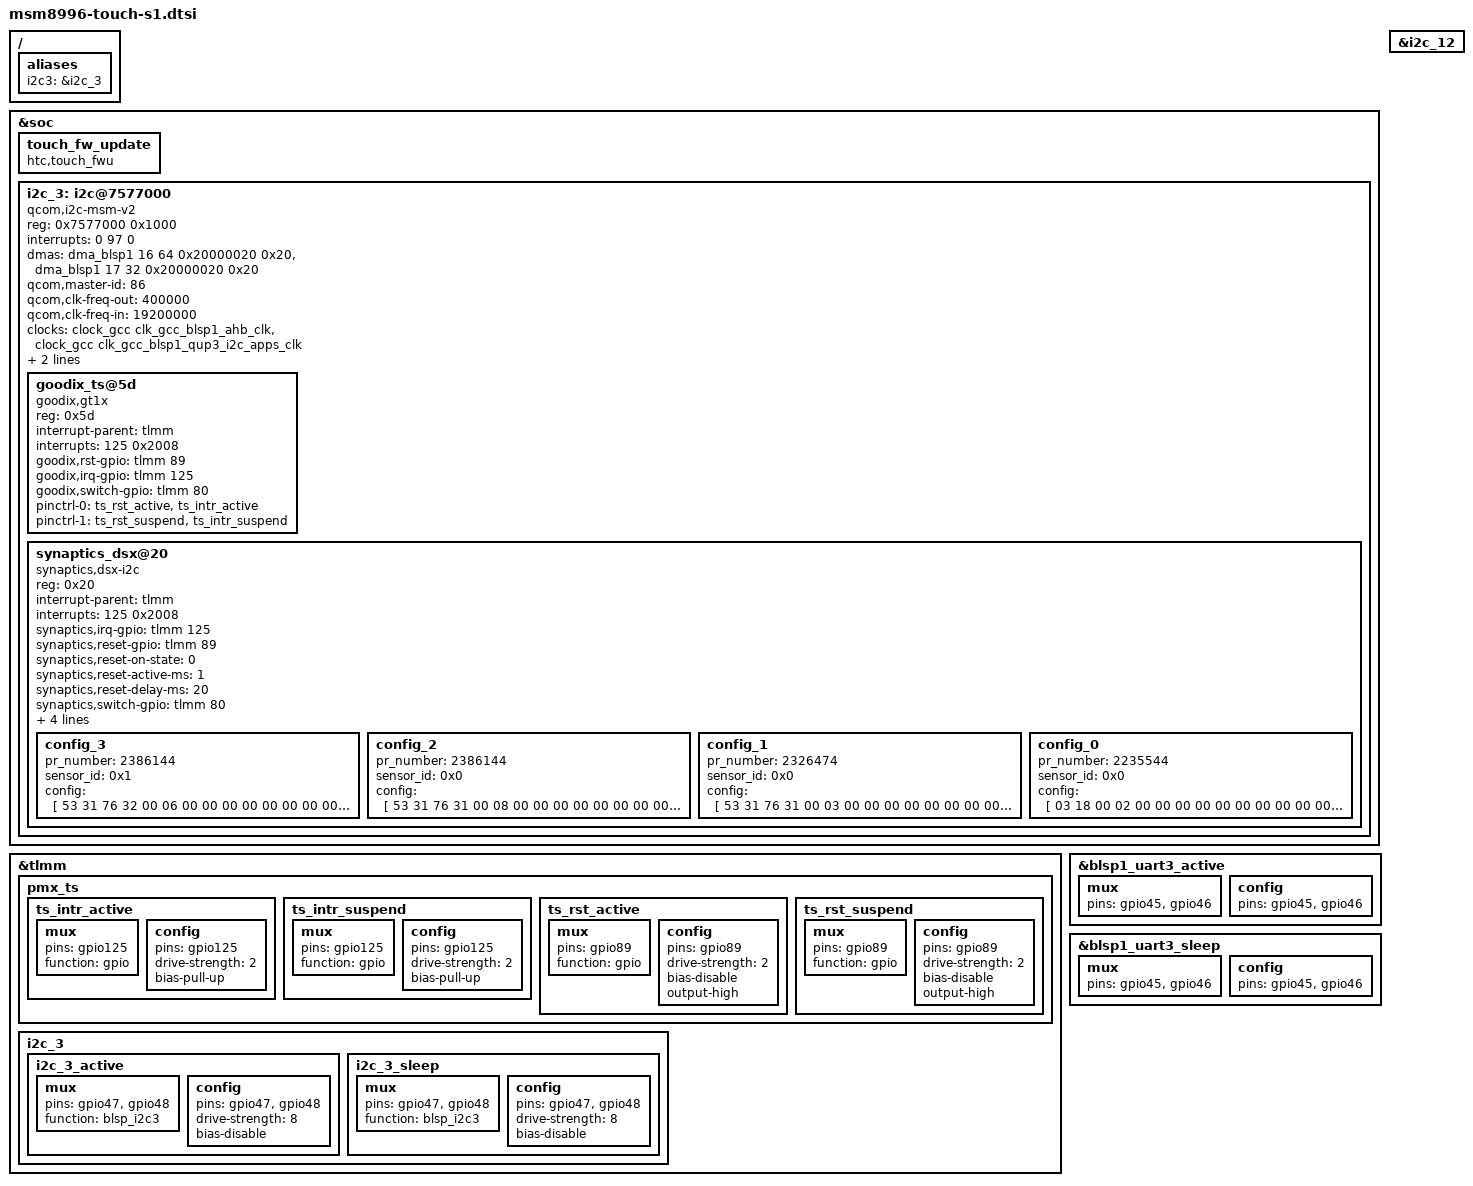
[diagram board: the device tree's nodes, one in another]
&soc {
	touch_fw_update {
		compatible = "htc,touch_fwu";
	};
};

&tlmm {
	pmx_ts {
		ts_intr_active:ts_intr_active {
			mux {
				pins = "gpio125";
				function = "gpio";
			};

			config {
				pins = "gpio125";
				drive-strength = <2>;
				bias-pull-up;
			};
		};
		ts_intr_suspend:ts_intr_suspend {
			mux {
				pins = "gpio125";
				function = "gpio";
			};

			config {
				pins = "gpio125";
				drive-strength = <2>;
				bias-pull-up;
			};
		};

		ts_rst_active:ts_rst_active {
			mux {
				pins = "gpio89";
				function = "gpio";
			};

			config {
				pins = "gpio89";
				drive-strength = <2>;
				bias-disable; /* No PULL */
				output-high;
			};
		};
		ts_rst_suspend:ts_rst_suspend {
			mux {
				pins = "gpio89";
				function = "gpio";
			};

			config {
				pins = "gpio89";
				drive-strength = <2>;
				bias-disable;
				output-high;
			};
		};
	};

	i2c_3 {
		i2c_3_active: i2c_3_active {
			mux {
				pins = "gpio47", "gpio48";
				function = "blsp_i2c3";
			};

			config {
				pins = "gpio47", "gpio48";
				drive-strength = <8>;
				bias-disable;
			};
		};

		i2c_3_sleep: i2c_3_sleep {
			mux {
				pins = "gpio47", "gpio48";
				function = "blsp_i2c3";
			};

			config {
				pins = "gpio47", "gpio48";
				drive-strength = <8>;
				bias-disable;
			};
		};
	};
};

&blsp1_uart3_active {
	mux {
		pins = "gpio45", "gpio46";
	};

	config {
		pins = "gpio45", "gpio46";
	};
};

&blsp1_uart3_sleep {
	mux {
		pins = "gpio45", "gpio46";
	};

	config {
		pins = "gpio45", "gpio46";
	};
};

/ {
	aliases {
		i2c3 = &i2c_3;
	};
};

&soc {
	i2c_3: i2c@7577000 { /* BLSP1 QUP3 */
		compatible = "qcom,i2c-msm-v2";
		#address-cells = <1>;
		#size-cells = <0>;
		reg = <0x7577000  0x1000>;
		reg-names = "qup_phys_addr";
		interrupt-names = "qup_irq";
		interrupts = <0 97 0>;
		dmas = <&dma_blsp1 16 64 0x20000020 0x20>,
			<&dma_blsp1 17 32 0x20000020 0x20>;
		dma-names = "tx", "rx";
		qcom,master-id = <86>;
		qcom,clk-freq-out = <400000>;
		qcom,clk-freq-in  = <19200000>;
		clock-names = "iface_clk", "core_clk";
		clocks = <&clock_gcc clk_gcc_blsp1_ahb_clk>,
			 <&clock_gcc clk_gcc_blsp1_qup3_i2c_apps_clk>;
		pinctrl-names = "i2c_active", "i2c_sleep";
		pinctrl-0 = <&i2c_3_active>;
		pinctrl-1 = <&i2c_3_sleep>;
	};
};

&i2c_12 {
	/delete-node/ synaptics@20;
};

&i2c_3 {
	goodix_ts@5d {
		compatible = "goodix,gt1x";
		reg = <0x5d>;
		interrupt-parent = <&tlmm>;
		interrupts = <125 0x2008>;
//		vdd_ana-supply = <&pm8994_l22>;
//		vcc_i2c-supply = <&pm8994_l18>;
		goodix,rst-gpio = <&tlmm 89 0x00>;
		goodix,irq-gpio = <&tlmm 125 0x00>;
		goodix,switch-gpio = <&tlmm 80 0x00>;
		pinctrl-names = "pmx_ts_active", "pmx_ts_suspend";
		pinctrl-0 = <&ts_rst_active &ts_intr_active>;
		pinctrl-1 = <&ts_rst_suspend &ts_intr_suspend>;
	};

	/delete-node/ synaptics_dsx@20;
	synaptics_dsx@20 {
		compatible = "synaptics,dsx-i2c";
		reg = <0x20>;
		interrupt-parent = <&tlmm>;
		interrupts = <125 0x2008>;
		synaptics,irq-gpio = <&tlmm 125 0x2008>;  /* IRQF_ONESHOT | IRQF_TRIGGER_LOW */
		synaptics,reset-gpio = <&tlmm 89 0x00>;
		synaptics,reset-on-state = <0>;
		synaptics,reset-active-ms = <1>;
		synaptics,reset-delay-ms = <20>;
		synaptics,switch-gpio = <&tlmm 80 0x00>;
		synaptics,update-feature = <3>;
		synaptics,tw-pin-mask = <0x3>;
		pinctrl-names = "pmx_ts_active", "pmx_ts_suspend";
		pinctrl-0 = <&ts_rst_active &ts_intr_active>;
		pinctrl-1 = <&ts_rst_suspend &ts_intr_suspend>;

		config_3 {
			pr_number     = <2386144>;
			sensor_id = <0x1>;
			config = [
				53 31 76 32 00 06 00 00
				00 00 00 00 00 00 00 00
				00 00 00 00 00 00 00 00
				00 00 00 00 00 00 00 00
				00 0F 01 0F 05 51 0E 37
				04 7F 07 46 3E 2B 3F 00
				00 20 20 10 1C 1E 05 CA
				0D B1 01 2D 1D 00 1B 00
				B1 CD 49 CE 25 0D 05 8C
				00 00 14 16 7D 0F 0A 87
				00 01 01 07 04 04 32 28
				08 7D 26 26 80 80 00 00
				C8 01 64 00 05 0A 00 FF
				05 01 28 FF C0 53 5B 80
				48 26 00 40 40 3C 50 00
				00 00 00 37 04 7F 07 3C
				32 00 00 00 00 37 04 7F
				07 1E 05 1E 04 0A 04 0A
				00 0A 04 04 00 0A 78 02
				00 7D 00 02 00 C8 00 00
				00 96 00 00 00 00 01 05
				0A 00 00 00 78 00 96 00
				32 00 00 00 00 00 00 00
				00 00 0D 00 00 14 03 0C
				0F 0A 00 4B 00 00 FF FF
				FF FF FF FF FF FF FF FF
				FF FF FF FF FF FF FF FF
				FF FF FF FF FF FF FF FF
				FF FF FF FF FF FF FF 00
				01 00 00 32 00 14 00 14
				00 64 00 64 00 10 00 10
				00 7D 00 7D 00 40 66 58
				1B 28 00 FF FF FF FF FF
				FF FF FF FF FF FF FF FF
				FF FF FF 01 00 00 00 00
				00 00 00 00 00 00 00 00
				00 00 00 00 00 00 00 00
				00 00 FF 00 FF 14 55 09
				0E 3C 0A 0F 64 64 00 00
				00 00 00 00 00 00 00 00
				00 00 00 00 00 00 00 00
				FF FF FF FF FF FF FF FF
				FF FF FF FF FF FF FF FF
				FF FF FF FF FF FF FF FF
				FF FF FF FF FF FF FF FF
				FF FF FF FF FF FF FF FF
				FF FF FF FF FF FF FF FF
				FF FF FF FF FF FF FF FF
				FF FF FF FF FF FF FF FF
				00 00 96 00 80 04 1B 00
				00 FF E8 03 FF FF BF 0A
				B8 0B 00 C0 80 04 10 0A
				18 00 79 08 0F 00 00 C8
				00 03 00 06 06 07 07 00
				C8 00 01 04 83 36 00 16
				00 00 00 02 00 01 2D 84
				35 00 16 00 01 00 05 00
				02 27 04 34 00 15 00 02
				00 05 00 02 28 83 33 00
				15 00 03 00 05 00 02 28
				83 32 00 14 00 04 00 05
				00 02 29 03 31 00 14 00
				05 00 05 00 02 29 83 2F
				00 13 00 07 00 03 00 01
				24 03 2D 00 13 00 09 00
				03 00 01 25 03 03 03 03
				03 03 03 03 03 03 03 03
				03 03 03 03 00 00 00 00
				00 00 00 00 00 00 00 00
				00 00 00 00 00 00 21 00
				06 00 28 00 0A 19 00 01
				1B 01 00 78 00 28 00 28
				00 3C 00 1E 03 0C 0C 14
				28 04 00 00 00 00 00 00
				00 00 00 00 15 00 80 07
				01 07 07 1D 1D 00 00 07
				07 01 07 07 1D 1D 00 00
				07 04 04 50 00 07 03 00
				36 22 00 05 0B 00 22 02
				00 00 00 0D 99 99 55 0D
				00 00 00 0D 00 00 00 0D
				AA AA 00 01 00 00 01 01
				00 01 00 80 80 80 80 80
				80 80 80 80 80 80 80 80
				80 80 80 80 80 80 80 80
				80 80 80 80 80 80 80 80
				80 80 80 80 80 80 80 80
				80 80 80 80 80 80 80 80
				80 80 80 80 80 80 80 80
				80 80 80 80 80 80 80 80
				80 80 80 80 80 80 80 00
				00 00 FF FF FF FF FF FF
				FF FF 51 51 51 51 CD 0D
				04 83 10 10 10 10 61 24
				64 01 16 12 11 0F 10 0B
				0A 05 04 18 1A 0D 13 0E
				08 09 FF FF FF FF FF FF
				FF FF FF FF FF FF FF FF
				FF FF FF FF 2F 28 29 2A
				2C 2B 26 25 23 24 22 35
				39 36 37 33 32 2D 27 34
				38 31 3A 3B 3E 3D 3C 3F
				FF FF FF FF FF FF 00 10
				00 10 00 10 00 10 80 80
				80 80 80 80 80 80 80 80
				80 80 80 80 80 80 80 80
				80 80 80 80 80 80 80 80
				80 80 80 80 80 80 80 80
				C0 B3 A6 9A 8D 80 80 80
				80 80 80 80 80 80 80 80
				80 80 80 80 80 80 80 80
				80 80 80 80 80 80 80 80
				80 80 00 18 00 18 00 10
				00 10 00 00 1C 1D 1E 1F
				FF FF FF FF 00 00 0F 00
				44 44 A0
			];
		};

		config_2 {
			pr_number     = <2386144>;
			sensor_id = <0x0>;
			config = [
				53 31 76 31 00 08 00 00
				00 00 00 00 00 00 00 00
				00 00 00 00 00 00 00 00
				00 00 00 00 00 00 00 00
				00 07 01 0F 05 51 0E 37
				04 7F 07 46 3E 2B 3F 00
				00 20 00 10 1C 1E 05 BF
				0F 31 02 2D 14 02 14 02
				C0 DA C0 DA 25 0D 05 8C
				00 00 10 12 82 0F 0A 78
				00 01 01 07 04 04 32 28
				08 7D 26 26 80 80 00 00
				C8 01 64 00 05 28 00 FF
				05 01 28 FF C0 53 5B 80
				52 1A 00 40 3A 46 50 00
				00 00 00 4C 04 6C 07 3C
				32 00 00 00 00 4C 04 6C
				07 1E 05 1E 04 0A 04 0A
				00 0A 04 04 00 0A 78 02
				00 7D 00 02 00 C8 00 00
				00 96 00 00 00 00 01 05
				0A 00 00 00 78 00 96 00
				32 00 00 00 00 00 00 00
				00 00 0D 00 00 14 03 0C
				0F 0A 00 4B 00 00 FF FF
				FF FF FF FF FF FF FF FF
				FF FF FF FF FF FF FF FF
				FF FF FF FF FF FF FF FF
				FF FF FF FF FF FF FF 00
				01 00 00 32 00 14 00 14
				00 64 00 64 00 10 00 10
				00 7D 00 7D 00 40 66 58
				1B 28 00 FF FF FF FF FF
				FF FF FF FF FF FF FF FF
				FF FF FF 01 00 00 00 00
				00 00 00 00 00 00 00 00
				00 00 00 00 00 00 00 00
				00 00 FF 00 FF 14 55 09
				0E 3C 0A 0F 64 64 00 00
				00 00 00 00 00 00 00 00
				00 00 00 00 00 00 00 00
				FF FF FF FF FF FF FF FF
				FF FF FF FF FF FF FF FF
				FF FF FF FF FF FF FF FF
				FF FF FF FF FF FF FF FF
				FF FF FF FF FF FF FF FF
				FF FF FF FF FF FF FF FF
				FF FF FF FF FF FF FF FF
				FF FF FF FF FF FF FF FF
				00 00 60 00 80 04 1B 00
				00 FF DC 05 FF FF CC 03
				40 1F 00 C0 80 04 10 0A
				18 00 79 08 06 00 01 B8
				0B 04 00 02 02 07 07 05
				B8 0B 01 04 83 36 00 16
				00 00 00 02 00 01 2D 84
				35 00 16 00 01 00 05 00
				02 27 04 34 00 15 00 02
				00 05 00 02 28 83 33 00
				15 00 03 00 05 00 02 28
				83 32 00 14 00 04 00 05
				00 02 29 03 31 00 14 00
				05 00 05 00 02 29 83 2F
				00 13 00 07 00 03 00 01
				24 03 2D 00 13 00 09 00
				03 00 01 25 03 03 03 03
				03 03 03 03 03 03 03 03
				03 03 03 03 00 00 00 00
				00 00 00 00 00 00 00 00
				00 00 00 00 00 00 21 00
				06 00 50 00 0A 19 00 01
				1B 01 06 46 00 28 00 28
				00 64 00 1E 03 0C 0C 14
				28 04 00 00 00 00 00 00
				00 00 00 00 15 00 80 07
				01 07 07 1D 1D 00 00 07
				07 01 07 07 1D 1D 00 00
				07 04 04 50 00 07 03 00
				36 22 00 05 0B 00 22 02
				00 00 00 0D DD DD 55 0D
				22 22 00 0D EE EE 00 0D
				EE EE AA 01 00 DA 00 01
				00 01 00 80 80 80 80 80
				80 80 80 80 80 80 80 80
				80 80 80 80 80 80 80 80
				80 80 80 80 80 80 80 80
				80 80 80 80 80 80 80 80
				80 80 80 80 80 80 80 80
				80 80 80 80 80 80 80 80
				80 80 80 80 80 80 80 80
				80 80 80 80 80 80 80 00
				00 00 FF FF FF FF FF FF
				FF FF 51 51 51 51 CD 0D
				04 83 10 10 10 10 61 24
				64 01 12 18 1A 38 36 31
				35 32 3A 37 14 34 15 33
				17 11 FF FF FF FF FF FF
				FF FF FF FF FF FF FF FF
				FF FF FF FF 30 28 2F 2A
				29 2C 27 2B 1B 1D 1E 1F
				1C 0D 10 0F 0C 07 0E 08
				09 03 06 02 0A 0B 04 05
				FF FF FF FF FF FF 00 10
				00 10 00 10 00 10 80 80
				80 80 80 80 80 80 80 80
				80 80 80 80 80 80 80 80
				80 80 80 80 80 80 80 80
				80 80 80 80 80 80 80 80
				C0 B3 A6 9A 8D 80 80 80
				80 80 80 80 80 80 80 80
				80 80 80 80 80 80 80 80
				80 80 80 80 80 80 80 80
				80 80 00 18 00 18 00 10
				00 10 00 00 16 19 24 39
				FF FF FF FF 0B 0B 04 00
				44 44 A0
			];
		};

		config_1 {
			pr_number     = <2326474>;
			sensor_id = <0x0>;
			config = [
				53 31 76 31 00 03 00 00
				00 00 00 00 00 00 00 00
				00 00 00 00 00 00 00 00
				00 00 00 00 00 00 00 00
				00 07 03 1E 05 51 0E 38
				04 80 07 46 3E 2B 3F 00
				00 20 00 10 1C 1E 05 BF
				0F 31 02 2D 14 02 14 02
				84 D2 81 D1 25 0D 05 8C
				00 00 0F 12 82 0F 0A 78
				00 01 01 07 04 04 32 28
				08 7D 26 26 80 80 00 00
				C8 01 64 00 05 0A 00 FF
				05 01 28 FF C0 53 5B 80
				4D 14 00 40 3A 32 50 00
				00 00 00 4C 04 6C 07 3C
				32 00 00 00 00 4C 04 6C
				07 1E 05 1E 04 0A 04 0A
				00 0A 04 04 00 0A 78 02
				00 7D 00 02 00 C8 00 00
				00 96 00 00 00 00 01 05
				0A 00 00 00 78 00 96 00
				32 00 00 00 00 00 00 00
				00 00 0D 00 00 14 03 0C
				0F 0A 00 4B 00 00 FF FF
				FF FF FF FF FF FF FF FF
				FF FF FF FF FF FF FF FF
				FF FF FF FF FF FF FF FF
				FF FF FF FF FF FF FF 00
				01 00 00 32 00 14 00 14
				00 64 00 64 00 10 00 10
				00 7D 00 7D 00 40 66 58
				1B 28 00 FF FF FF FF FF
				FF FF FF FF FF FF FF FF
				FF FF FF 01 00 00 00 00
				00 00 00 00 00 00 00 00
				00 00 00 00 00 00 00 00
				00 00 FF 00 FF 14 55 09
				0E 3C 0A 0F 64 64 00 00
				00 00 00 00 00 00 00 00
				00 00 00 00 00 00 00 00
				FF FF FF FF FF FF FF FF
				FF FF FF FF FF FF FF FF
				FF FF FF FF FF FF FF FF
				FF FF FF FF FF FF FF FF
				FF FF FF FF FF FF FF FF
				FF FF FF FF FF FF FF FF
				FF FF FF FF FF FF FF FF
				FF FF FF FF FF FF FF FF
				00 00 60 00 80 04 1B 00
				00 FF 2C 01 FF FF CC 03
				E8 03 00 C0 80 04 10 0A
				18 00 79 08 08 00 01 2C
				01 06 00 02 02 07 07 05
				FA 00 01 04 83 36 00 16
				00 00 00 02 00 01 2D 84
				35 00 16 00 01 00 05 00
				02 27 04 34 00 15 00 02
				00 05 00 02 28 83 33 00
				15 00 03 00 05 00 02 28
				83 32 00 14 00 04 00 05
				00 02 29 03 31 00 14 00
				05 00 05 00 02 29 83 2F
				00 13 00 07 00 03 00 01
				24 03 2D 00 13 00 09 00
				03 00 01 25 03 03 03 03
				03 03 03 03 03 03 03 03
				03 03 03 03 00 00 00 00
				00 00 00 00 00 00 00 00
				00 00 00 00 00 00 21 00
				06 00 A6 00 14 32 00 01
				1B 01 06 46 46 50 00 50
				00 50 50 1E 03 0C 0C 14
				28 04 00 00 00 00 00 00
				00 00 00 00 15 00 80 07
				01 07 07 1D 1D 00 00 07
				07 01 07 07 1D 1D 00 00
				07 04 04 50 00 07 03 00
				36 22 00 05 0B 00 22 02
				00 00 00 0D DD DD 55 0D
				22 22 00 01 50 0D 00 00
				00 0D AA AA 00 00 00 00
				FF FF FF FF FF FF FF FF
				51 51 51 51 CD 0D 04 83
				10 10 10 10 61 24 64 01
				12 18 1A 38 36 31 35 32
				3A 37 14 34 15 33 17 11
				FF FF FF FF FF FF FF FF
				FF FF FF FF FF FF FF FF
				FF FF 30 28 2F 2A 29 2C
				27 2B 1B 1D 1E 1F 1C 0D
				10 0F 0C 07 0E 08 09 03
				06 02 0A 0B 04 05 FF FF
				FF FF FF FF 00 10 00 10
				00 10 00 10 80 80 80 80
				80 80 80 80 80 80 80 80
				80 80 80 80 80 80 80 80
				80 80 80 80 80 80 80 80
				80 80 80 80 80 80 80 80
				80 80 80 80 80 80 80 80
				80 80 80 80 80 80 80 80
				80 80 80 80 80 80 80 80
				80 80 80 80 80 80 80 80
				00 10 00 10 00 10 00 10
				00 00 16 19 24 39 FF FF
				FF FF 0B 0B 04 00 44 44
				78
			];
		};

		config_0 {
			pr_number     = <2235544>;
			sensor_id = <0x0>;
			config = [
				03 18 00 02 00 00 00 00
				00 00 00 00 00 00 00 00
				00 00 00 00 00 00 00 00
				00 00 00 00 00 00 00 00
				04 7F 03 1E 05 51 0E 37
				04 7F 07 46 3E 2F 3F 03
				03 03 03 10 1C 1E 05 F5
				28 1E 05 28 30 00 30 00
				F0 D2 F0 D2 25 0D 05 8C
				00 00 05 0F 80 0F 0A 20
				00 01 01 07 04 04 0A C0
				19 64 26 26 80 80 00 00
				C8 C0 53 5B 80 5A 19 01
				40 40 32 50 00 00 00 00
				4C 04 6C 07 3C 32 00 00
				00 00 4C 04 6C 07 1E 05
				1E 04 0A 04 0A 00 0A 04
				04 00 0A 78 02 00 7D 00
				02 00 C8 00 00 00 96 00
				00 00 00 00 15 0A 00 00
				00 78 00 96 00 32 00 00
				00 00 00 00 00 00 00 0D
				00 00 14 03 0C 0F 0A 00
				4B 00 00 FF FF FF FF FF
				FF FF FF FF FF FF FF FF
				FF FF FF FF FF FF FF FF
				FF FF FF FF FF FF FF FF
				FF FF FF FF 00 01 00 00
				32 00 14 00 14 00 64 00
				64 00 10 00 10 00 7D 00
				7D 00 40 66 58 1B 28 00
				FF FF FF FF FF FF FF FF
				FF FF FF FF FF FF FF FF
				01 00 00 00 00 00 00 00
				00 00 00 00 00 00 00 00
				00 00 00 00 00 00 00 FF
				00 FF 14 55 09 0E 3C 0A
				0F 64 64 00 00 00 00 00
				00 00 00 00 00 00 00 00
				00 00 00 00 00 FF FF FF
				FF FF FF FF FF FF FF FF
				FF FF FF FF FF FF FF FF
				FF FF FF FF FF FF FF FF
				FF FF FF FF FF FF FF FF
				FF FF FF FF FF FF FF FF
				FF FF FF FF FF FF FF FF
				FF FF FF FF FF FF FF FF
				FF FF FF FF FF 00 01 8C
				00 80 04 1B 00 00 FF FF
				FF FF FF FF FF FF FF 00
				C0 80 04 10 0A 18 00 79
				00 FF FF 01 FF FF FF FF
				04 04 07 07 02 FF FF 01
				04 05 40 00 17 00 00 00
				02 00 01 2A 85 3E 00 17
				00 01 00 02 00 01 2C 84
				3D 00 17 00 02 00 02 00
				01 2D 84 3C 00 16 00 03
				00 05 00 02 26 84 3B 00
				16 00 04 00 05 00 02 27
				84 39 00 15 00 05 00 05
				00 02 28 84 38 00 15 00
				06 00 05 00 02 28 84 37
				00 14 00 07 00 05 00 02
				29 02 02 02 02 02 02 02
				02 02 02 02 02 02 02 02
				02 00 00 00 00 00 00 00
				00 00 00 00 00 00 00 00
				00 00 00 1C 00 06 00 A6
				00 14 64 00 01 1B 01 00
				08 08 A0 00 A0 00 50 50
				1E 03 0C 0C 14 28 04 00
				00 00 00 00 00 00 00 00
				00 16 0A 80 07 07 07 06
				1B 1B 00 00 07 07 07 07
				06 1B 1B 00 00 07 04 04
				50 00 07 05 00 40 38 00
				05 0B 00 22 02 00 00 00
				0D DD DD FF 0D EE EE 55
				00 00 0D EE EE 00 0D EE
				EE AA 00 00 00 FF FF FF
				FF FF FF FF FF 51 51 51
				51 CD 0D 04 83 10 10 10
				10 61 24 64 01 12 18 1A
				38 36 31 35 32 3A 37 14
				34 15 33 17 11 FF FF FF
				FF FF FF FF FF FF FF FF
				FF FF FF FF FF FF FF 30
				28 2F 2A 29 2C 27 2B 1B
				1D 1E 1F 1C 0D 10 0F 0C
				07 0E 08 09 03 06 02 0A
				0B 04 05 FF FF FF FF FF
				FF 00 10 00 10 00 10 00
				10 80 80 80 80 80 80 80
				80 80 80 80 80 80 80 80
				80 80 80 80 80 80 80 80
				80 80 80 80 80 80 80 80
				80 80 80 80 80 80 80 80
				80 80 80 80 80 80 80 80
				80 80 80 80 80 80 80 80
				80 80 80 80 80 80 80 80
				80 80 80 80 80 00 10 00
				10 00 10 00 10 00 00 16
				19 24 39 FF FF FF FF 0B
				0B 04 00 00 00
			];
		};
	};
};
